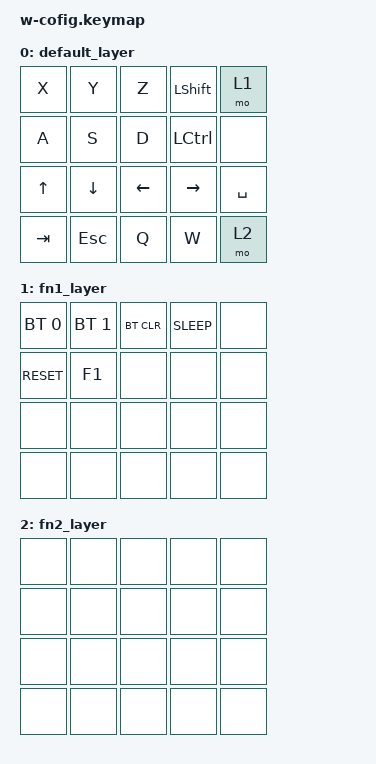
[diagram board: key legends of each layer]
#include <behaviors.dtsi>
#include <dt-bindings/zmk/keys.h>
#include <dt-bindings/zmk/bt.h>

/ {
    keymap {
        compatible = "zmk,keymap";

        // 层0：格斗层（14个操作键）
        default_layer {
            bindings = <
    &kp X   &kp Y   &kp Z   &kp LSHIFT    &mo 1          // 行1：拳拳拳 + FN1
    &kp A   &kp S   &kp D   &kp LCTRL     &none          // 行2：脚脚脚
    &kp UP  &kp DOWN&kp LEFT&kp RIGHT     &kp SPACE      // 行3：方向+闪避
    &kp TAB &kp ESC &kp Q   &kp W         &mo 2          // 行4：功能 + FN2
            >;
        };

        // 层1：功能（蓝牙、重置）
        fn1_layer {
            bindings = <
    &bt BT_SEL 0 &bt BT_SEL 1 &bt BT_CLR &kp SLEEP  &none
    &kp RESET    &kp F1       &none      &none      &none
    &none        &none        &none      &none      &none
    &none        &none        &none      &none      &none
            >;
        };

        // 层2：备用
        fn2_layer {
            bindings = <
    &none &none &none &none &none
    &none &none &none &none &none
    &none &none &none &none &none
    &none &none &none &none &none
            >;
        };
    };
};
